# GD32F3x0 register map
File version: 1.0
CPU: CM4 r2p1, little endian, no MPU, no FPU, 4 interrupt priority bits
Registers are 32-bit, read-write, reset 0x0 unless marked. A register's access mark holds for its fields unless they carry their own. Offsets are from the block's base; [hi:lo] are bit positions; {n}, {i} and the like mark numbered series; 'fields as' and 'values as' point back to an identical list.

## USBFS_DEVICE — USB on the go full speed device
Base 0x50000800
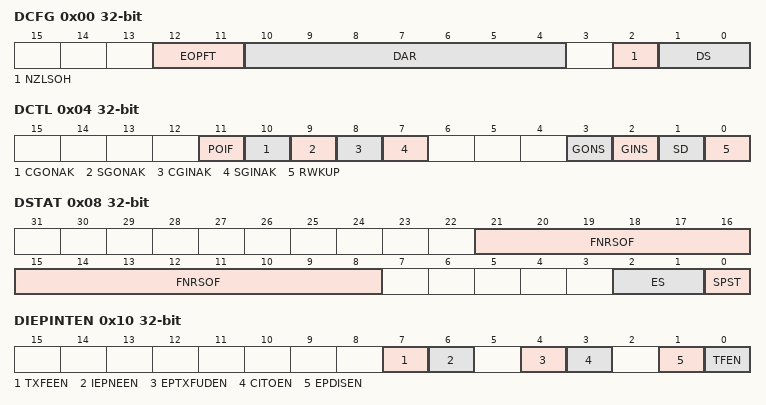
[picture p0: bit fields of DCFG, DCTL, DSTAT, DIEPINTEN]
0x00 DCFG — device configuration register (DCFG)
  [12:11] EOPFT — end of periodic frame time
  [10:4] DAR — Device address
  [2] NZLSOH — Non-zero-length status OUT handshake
  [1:0] DS — Device speed
0x04 DCTL access per field — device control register (DCTL)
  [11] POIF rw — Power-on initialization flag
  [10] CGONAK wo — Clear global OUT NAK
  [9] SGONAK wo — Set global OUT NAK
  [8] CGINAK wo — Clear global IN NAK
  [7] SGINAK wo — Set global IN NAK
  [3] GONS ro — Global OUT NAK status
  [2] GINS ro — Global IN NAK status
  [1] SD rw — Soft disconnect
  [0] RWKUP rw — Remote wakeup
0x08 DSTAT ro — device status register (DSTAT)
  [21:8] FNRSOF — Frame number of the received SOF
  [2:1] ES — Enumerated speed
  [0] SPST — Suspend status
0x10 DIEPINTEN — device IN endpoint common interrupt mask register (DIEPINTEN)
  [7] TXFEEN — Trabsmit FIFO empty interrupt enable
  [6] IEPNEEN — IN endpoint NAK effective interrupt enable
  [4] EPTXFUDEN — Endpoint Tx FIFO underrun interrupt enable bit
  [3] CITOEN — Control IN timeout condition interrupt enable (Non-isochronous endpoints)
  [1] EPDISEN — Endpoint disabled interrupt enable
  [0] TFEN — Transfer finished interrupt enable
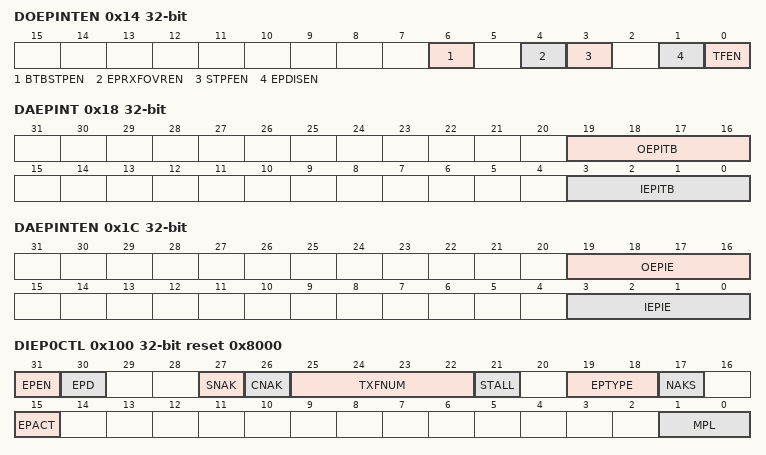
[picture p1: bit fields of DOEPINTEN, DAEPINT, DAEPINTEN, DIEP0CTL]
0x14 DOEPINTEN — device OUT endpoint common interrupt enable register (DOEPINTEN)
  [6] BTBSTPEN — Back-to-back SETUP packets interrupt enable
  [4] EPRXFOVREN — Endpoint Rx FIFO overrun interrupt enable
  [3] STPFEN — SETUP phase finished interrupt enable
  [1] EPDISEN — Endpoint disabled interrupt enable
  [0] TFEN — Transfer finished interrupt enable
0x18 DAEPINT ro — device all endpoints interrupt register (DAEPINT)
  [19:16] OEPITB — Device all OUT endpoint interrupt bits
  [3:0] IEPITB — Device all IN endpoint interrupt bits
0x1C DAEPINTEN — Device all endpoints interrupt enable register (DAEPINTEN)
  [19:16] OEPIE — OUT endpoint interrupt enable bits
  [3:0] IEPIE — IN EP interrupt interrupt enable bits
0x28 DVBUSDT reset 0x17D7 — device VBUS discharge time register
  [15:0] DVBUSDT — Device VBUS discharge time
0x2C DVBUSPT reset 0x5B8 — device VBUS pulsing time register
  [11:0] DVBUSPT — Device VBUS pulsing time
0x34 DIEPFEINTEN — device IN endpoint FIFO empty interrupt enable register
  [3:0] IEPTXFEIE — IN EP Tx FIFO empty interrupt enable bits
0x100 DIEP0CTL access per field reset 0x8000 — device IN endpoint 0 control register (DIEP0CTL)
  [31] EPEN rw — Endpoint enable
  [30] EPD rw — Endpoint disable
  [27] SNAK wo — Set NAK
  [26] CNAK wo — Clear NAK
  [25:22] TXFNUM rw — TxFIFO number
  [21] STALL rw — STALL handshake
  [19:18] EPTYPE ro — Endpoint type
  [17] NAKS ro — NAK status
  [15] EPACT ro — endpoint active
  [1:0] MPL rw — Maximum packet length
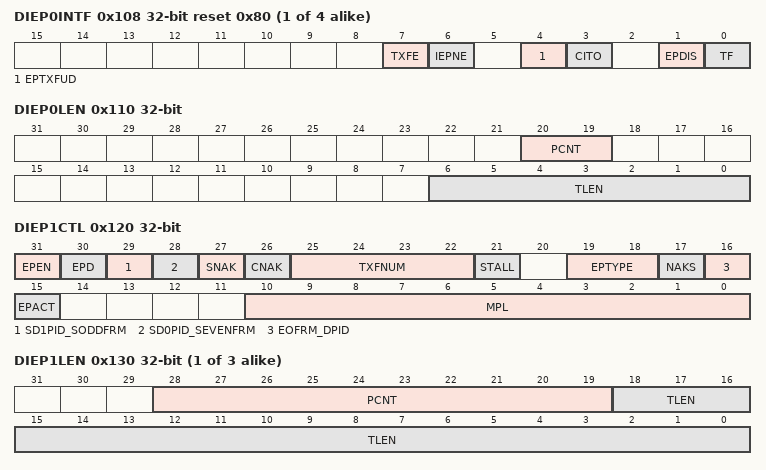
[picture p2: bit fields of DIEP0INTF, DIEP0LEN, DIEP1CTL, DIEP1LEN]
{0x108+0x20*i} DIEP{i}INTF access per field reset 0x80 (i=0..3) — device endpoint-{i} interrupt register
  [7] TXFE ro — Transmit FIFO empty
  [6] IEPNE rw — IN endpoint NAK effective
  [4] EPTXFUD rw — Endpoint Tx FIFO underrun
  [3] CITO rw — Control in timeout interrupt
  [1] EPDIS rw — Endpoint finished
  [0] TF rw — Transfer finished
0x110 DIEP0LEN — device IN endpoint-0 transfer length register
  [20:19] PCNT — Packet count
  [6:0] TLEN — Transfer length
{0x118+0x20*i} DIEP{i}TFSTAT ro reset 0x200 (i=0..3) — device IN endpoint {i} transmit FIFO status register
  [15:0] IEPTFS — IN endpoint TxFIFO space remaining
0x120 DIEP1CTL access per field — device in endpoint-1 control register
  [31] EPEN rw — Endpoint enable
  [30] EPD rw — Endpoint disable
  [29] SD1PID_SODDFRM wo — Set DATA1 PID/Set odd frame
  [28] SD0PID_SEVENFRM wo — SD0PID/SEVNFRM
  [27] SNAK wo — Set NAK
  [26] CNAK wo — Clear NAK
  [25:22] TXFNUM rw — Tx FIFO number
  [21] STALL rw — STALL handshake
  [19:18] EPTYPE rw — Endpoint type
  [17] NAKS ro — NAK status
  [16] EOFRM_DPID ro
  [15] EPACT rw — Endpoint active
  [10:0] MPL rw — maximum packet length
{0x110+0x20*i} DIEP{i}LEN (i=1..3) — device IN endpoint-{i} transfer length register
  [28:19] PCNT — Packet count
  [18:0] TLEN — Transfer length
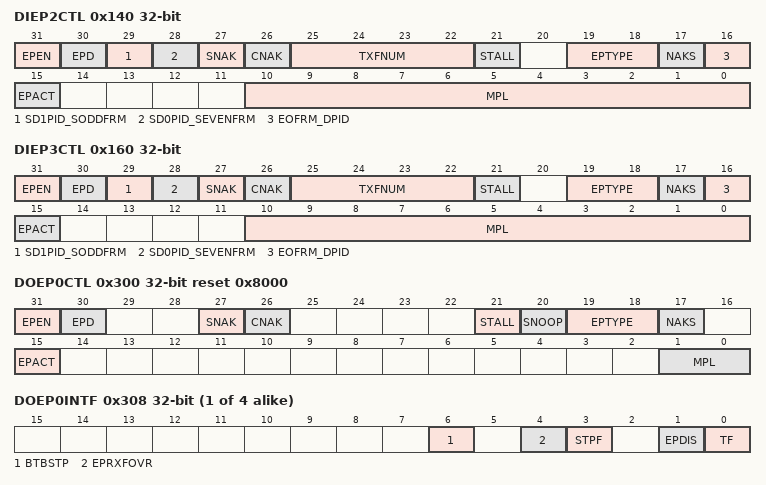
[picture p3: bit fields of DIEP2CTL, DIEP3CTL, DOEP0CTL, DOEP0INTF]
0x140 DIEP2CTL access per field — device endpoint-2 control register
  fields as DIEP1CTL
0x160 DIEP3CTL access per field — device endpoint-3 control register
  fields as DIEP1CTL
0x300 DOEP0CTL access per field reset 0x8000 — device endpoint-0 control register
  [31] EPEN wo — Endpoint enable
  [30] EPD ro — Endpoint disable
  [27] SNAK wo — Set NAK
  [26] CNAK wo — Clear NAK
  [21] STALL rw — STALL handshake
  [20] SNOOP rw — Snoop mode
  [19:18] EPTYPE ro — Endpoint type
  [17] NAKS ro — NAK status
  [15] EPACT ro — Endpoint active
  [1:0] MPL ro — Maximum packet length
{0x308+0x20*i} DOEP{i}INTF (i=0..3) — device out endpoint-{i} interrupt flag register
  [6] BTBSTP — Back-to-back SETUP packets
  [4] EPRXFOVR — Endpoint Rx FIFO overrun
  [3] STPF — Setup phase finished
  [1] EPDIS — Endpoint disabled
  [0] TF — Transfer finished
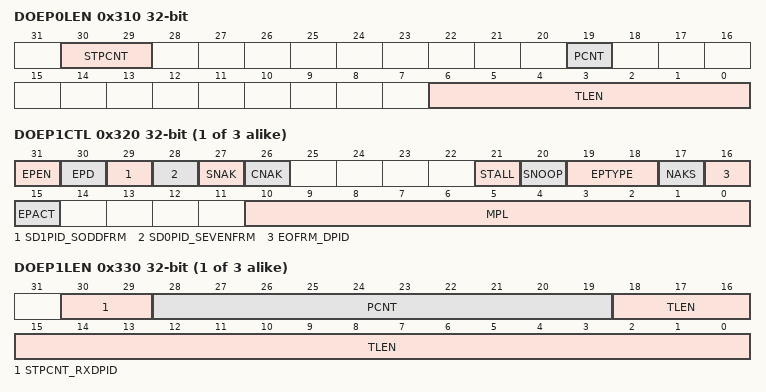
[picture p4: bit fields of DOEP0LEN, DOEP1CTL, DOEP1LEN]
0x310 DOEP0LEN — device OUT endpoint-0 transfer length register
  [30:29] STPCNT — SETUP packet count
  [19] PCNT — Packet count
  [6:0] TLEN — Transfer length
{0x300+0x20*i} DOEP{i}CTL access per field (i=1..3) — device endpoint-{i} control register
  [31] EPEN rw — Endpoint enable
  [30] EPD rw — Endpoint disable
  [29] SD1PID_SODDFRM wo
  [28] SD0PID_SEVENFRM wo
  [27] SNAK wo — Set NAK
  [26] CNAK wo — Clear NAK
  [21] STALL rw — STALL handshake
  [20] SNOOP rw — Snoop mode
  [19:18] EPTYPE rw — Endpoint type
  [17] NAKS ro — NAK status
  [16] EOFRM_DPID ro
  [15] EPACT rw — Endpoint active
  [10:0] MPL rw — maximum packet length
{0x310+0x20*i} DOEP{i}LEN (i=1..3) — device OUT endpoint-{i} transfer length register
  [30:29] STPCNT_RXDPID — SETUP packet count/Received data PID
  [28:19] PCNT — Packet count
  [18:0] TLEN — Transfer length
